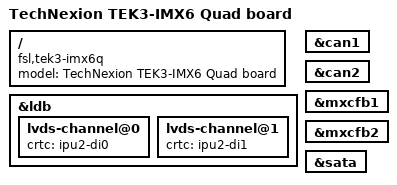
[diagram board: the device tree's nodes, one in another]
/*
 * Copyright 2018 TechNexion Ltd.
 *
 * Author: Richard Hu <richard.hu@technexion.com>
 *	   Wig Cheng  <wig.cheng@technexion.com>
 *
 * The code contained herein is licensed under the GNU General Public
 * License. You may obtain a copy of the GNU General Public License
 * Version 2 or later at the following locations:
 *
 * http://www.opensource.org/licenses/gpl-license.html
 * http://www.gnu.org/copyleft/gpl.html
 */

/dts-v1/;

#include <dt-bindings/interrupt-controller/irq.h>
#include "imx6q.dtsi"
#include "imx6qdl-tek3.dtsi"

/ {
	model = "TechNexion TEK3-IMX6 Quad board";
	compatible = "fsl,tek3-imx6q", "fsl,imx6q";
};

&ldb {
	lvds-channel@0 {
		crtc = "ipu2-di0";
	};

	lvds-channel@1 {
		crtc = "ipu2-di1";
	};
};

&can1{
	status = "okay";
};

&can2{
	status = "okay";
};

&mxcfb1 {
	status = "okay";
};

&mxcfb2 {
	status = "okay";
};
#if 0
&mxcfb3 {
	status = "okay";
};

&mxcfb4 {
	status = "okay";
};
#endif
&sata {
	status = "okay";
};
